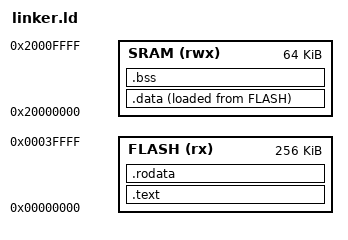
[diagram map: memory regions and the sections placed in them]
MEMORY
{
    FLASH (rx)  : ORIGIN = 0x00000000, LENGTH = 256K
    SRAM  (rwx) : ORIGIN = 0x20000000, LENGTH = 64K
}

SECTIONS
{
    .text : 
    {
        . = ALIGN(4);
        *(.exception_handlers)
        *(.text)
        . = ALIGN(4);
        _text_end = .;
    } > FLASH

    .rodata :
    {
        . = ALIGN(4);
        *(.rodata)
        . = ALIGN(4);
    } > FLASH

    .data : 
    {
        . = ALIGN(4);
        _data_start = .;
        *(.data)
        . = ALIGN(4);
        _data_end = .;
    } > SRAM AT> FLASH

    .bss :
    {
        . = ALIGN(4);
        _bss_start = .;
        *(.bss)
        . = ALIGN(4);
        _bss_end = .;
    } > SRAM
}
